# CM32M4xxR register map
Vendor: CMIOT XinSheng Tech Ltd.; File version: 2.0
Registers are 32-bit, read-write, reset 0x0 unless marked. A register's access mark holds for its fields unless they carry their own. Offsets are from the block's base; [hi:lo] are bit positions; {n}, {i} and the like mark numbered series.

## GPIOA — General purpose I/O
Base 0x40010800
Same registers: GPIOB 0x40010C00, GPIOC 0x40011000, GPIOD 0x40011400, GPIOE 0x40011800, GPIOF 0x40011C00, GPIOG 0x40012000
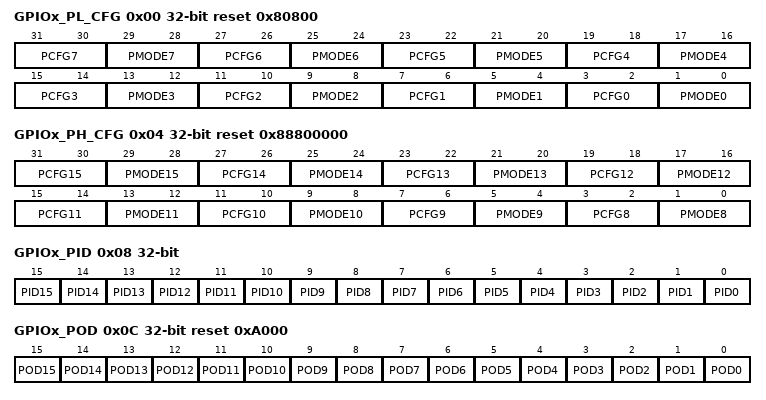
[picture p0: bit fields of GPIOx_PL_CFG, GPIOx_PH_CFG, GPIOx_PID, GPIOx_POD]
0x00 GPIOx_PL_CFG reset 0x80800
  [4n+3:4n+2] PCFG{n} (n=0..7), [4n+1:4n] PMODE{n} (n=0..7)
0x04 GPIOx_PH_CFG reset 0x88800000
  [4n-29:4n-30] PCFG{n} (n=8..15), [4n-31:4n-32] PMODE{n} (n=8..15)
0x08 GPIOx_PID
  [n] PID{n} (n=0..15)
0x0C GPIOx_POD reset 0xA000
  [n] POD{n} (n=0..15)
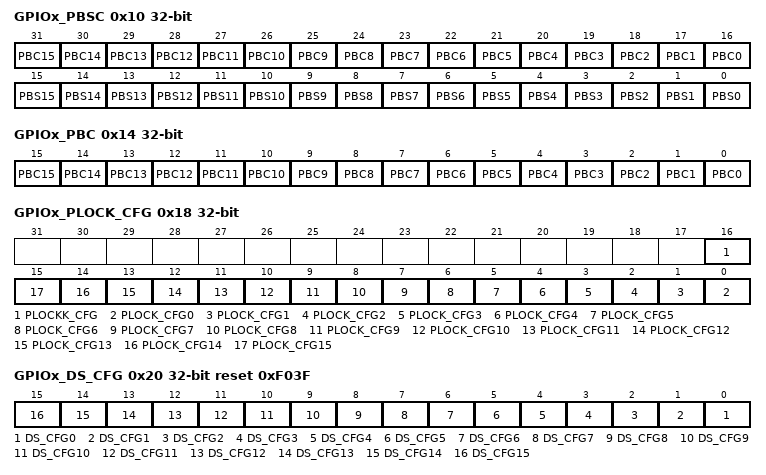
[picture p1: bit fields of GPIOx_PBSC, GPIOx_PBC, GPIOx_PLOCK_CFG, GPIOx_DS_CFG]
0x10 GPIOx_PBSC
  [n+16] PBC{n} (n=0..15), [n] PBS{n} (n=0..15)
0x14 GPIOx_PBC
  [n] PBC{n} (n=0..15)
0x18 GPIOx_PLOCK_CFG
  [16] PLOCKK_CFG, [n] PLOCK_CFG{n} (n=0..15)
0x20 GPIOx_DS_CFG reset 0xF03F
  [n] DS_CFG{n} (n=0..15)
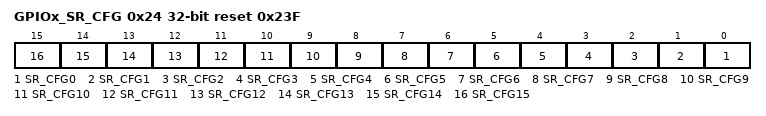
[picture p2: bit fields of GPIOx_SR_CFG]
0x24 GPIOx_SR_CFG reset 0x23F
  [n] SR_CFG{n} (n=0..15)

## AFIO — Alternate function I/O
Base 0x40010000
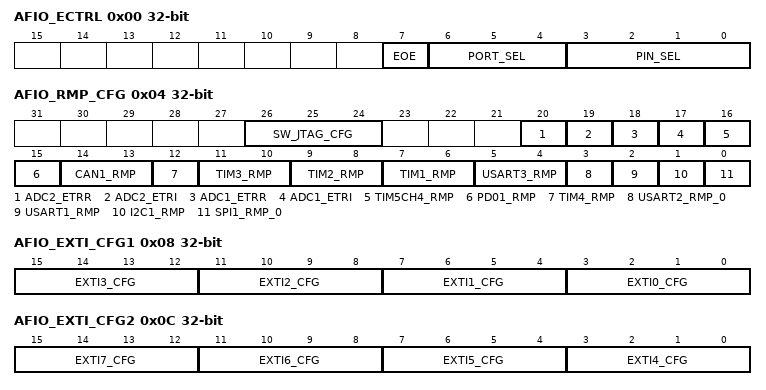
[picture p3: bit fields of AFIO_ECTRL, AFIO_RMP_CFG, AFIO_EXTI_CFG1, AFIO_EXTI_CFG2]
0x00 AFIO_ECTRL
  [7] EOE, [6:4] PORT_SEL, [3:0] PIN_SEL
0x04 AFIO_RMP_CFG
  [26:24] SW_JTAG_CFG, [20] ADC2_ETRR, [19] ADC2_ETRI, [18] ADC1_ETRR, [17] ADC1_ETRI, [16] TIM5CH4_RMP, [15] PD01_RMP, [14:13] CAN1_RMP, [12] TIM4_RMP, [11:10] TIM3_RMP, [9:8] TIM2_RMP, [7:6] TIM1_RMP, [5:4] USART3_RMP, [3] USART2_RMP_0, [2] USART1_RMP, [1] I2C1_RMP, [0] SPI1_RMP_0
0x08 AFIO_EXTI_CFG1
  [4n+3:4n] EXTI{n}_CFG (n=0..3)
0x0C AFIO_EXTI_CFG2
  [4n-13:4n-16] EXTI{n}_CFG (n=4..7)
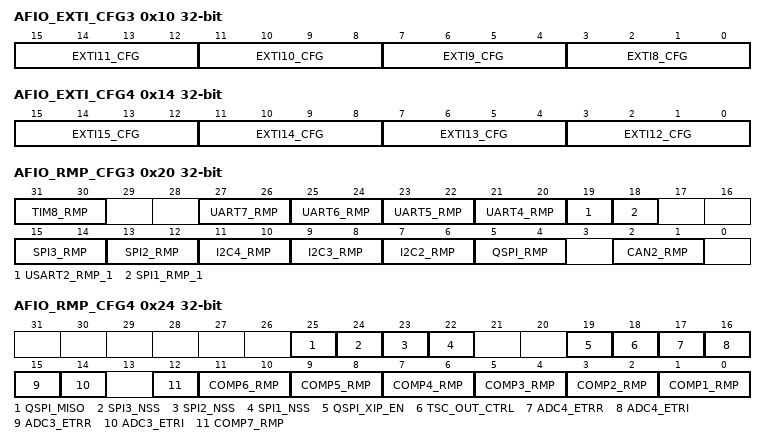
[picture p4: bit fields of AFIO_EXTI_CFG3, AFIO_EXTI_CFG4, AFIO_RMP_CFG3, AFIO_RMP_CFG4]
0x10 AFIO_EXTI_CFG3
  [4n-29:4n-32] EXTI{n}_CFG (n=8..11)
0x14 AFIO_EXTI_CFG4
  [4n-45:4n-48] EXTI{n}_CFG (n=12..15)
0x20 AFIO_RMP_CFG3
  [31:30] TIM8_RMP, [2n+13:2n+12] UART{n}_RMP (n=4..7), [19] USART2_RMP_1, [18] SPI1_RMP_1, [15:14] SPI3_RMP, [13:12] SPI2_RMP, [11:10] I2C4_RMP, [9:8] I2C3_RMP, [7:6] I2C2_RMP, [5:4] QSPI_RMP, [2:1] CAN2_RMP
0x24 AFIO_RMP_CFG4
  [25] QSPI_MISO, [24] SPI3_NSS, [23] SPI2_NSS, [22] SPI1_NSS, [19] QSPI_XIP_EN, [18] TSC_OUT_CTRL, [17] ADC4_ETRR, [16] ADC4_ETRI, [15] ADC3_ETRR, [14] ADC3_ETRI, [12] COMP7_RMP, [2n-1:2n-2] COMP{n}_RMP (n=1..6)
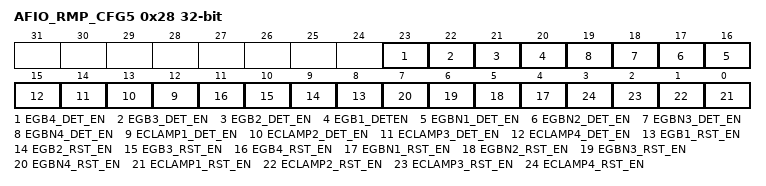
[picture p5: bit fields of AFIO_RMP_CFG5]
0x28 AFIO_RMP_CFG5
  [23] EGB4_DET_EN, [22] EGB3_DET_EN, [21] EGB2_DET_EN, [20] EGB1_DETEN, [n+15] EGBN{n}_DET_EN (n=1..4), [n+11] ECLAMP{n}_DET_EN (n=1..4), [n+7] EGB{n}_RST_EN (n=1..4), [n+3] EGBN{n}_RST_EN (n=1..4), [n-1] ECLAMP{n}_RST_EN (n=1..4)

## EXTI — external interrupt/event controller
Base 0x40010400
0x00 EXTI_IMASK
  [21:0] IMASK
0x04 EXTI_EMASK
  [21:0] EMASK
0x08 EXTI_RT_CFG
  [21:0] RT_CFG
0x0C EXTI_FT_CFG
  [21:0] FT_CFG
0x10 EXTI_SWIE
  [21:0] SWIE
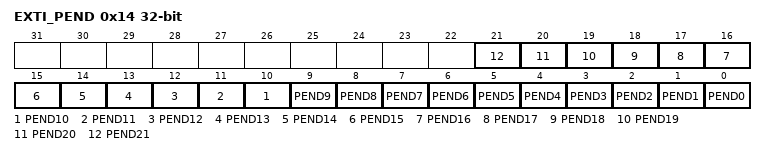
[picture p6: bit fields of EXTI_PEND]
0x14 EXTI_PEND
  [n] PEND{n} (n=0..21)
0x18 EXTI_TS_SEL
  [3:0] TSSEL

## FLASH — interal FLASH controller
Base 0x40022000
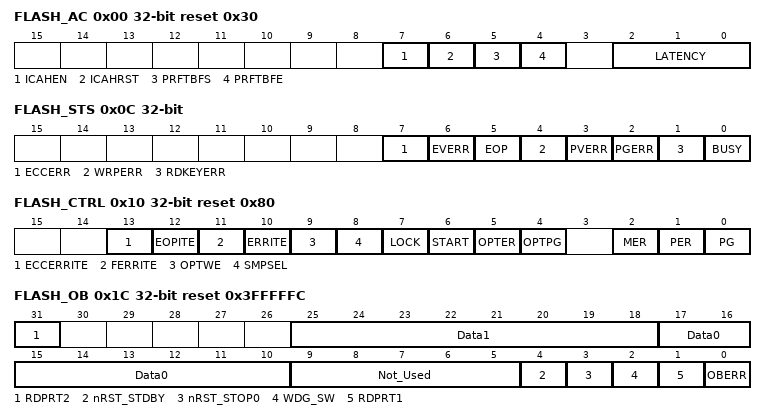
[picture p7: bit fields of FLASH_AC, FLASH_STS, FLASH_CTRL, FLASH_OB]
0x00 FLASH_AC reset 0x30
  [7] ICAHEN, [6] ICAHRST, [5] PRFTBFS, [4] PRFTBFE, [2:0] LATENCY
0x04 FLASH_KEY
  [31:0] FKEY
0x08 FLASH_OPTKEY
0x0C FLASH_STS
  [7] ECCERR, [6] EVERR, [5] EOP, [4] WRPERR, [3] PVERR, [2] PGERR, [1] RDKEYERR, [0] BUSY
0x10 FLASH_CTRL reset 0x80
  [13] ECCERRITE, [12] EOPITE, [11] FERRITE, [10] ERRITE, [9] OPTWE, [8] SMPSEL, [7] LOCK, [6] START, [5] OPTER, [4] OPTPG, [2] MER, [1] PER, [0] PG
0x14 FLASH_ADD
  [31:0] FADD
0x1C FLASH_OB reset 0x3FFFFFC
  [31] RDPRT2, [25:18] Data1, [17:10] Data0, [9:5] Not_Used, [4] nRST_STDBY, [3] nRST_STOP0, [2] WDG_SW, [1] RDPRT1, [0] OBERR
0x20 FLASH_WRP reset 0xFFFFFFFF
  [31:0] WRPT
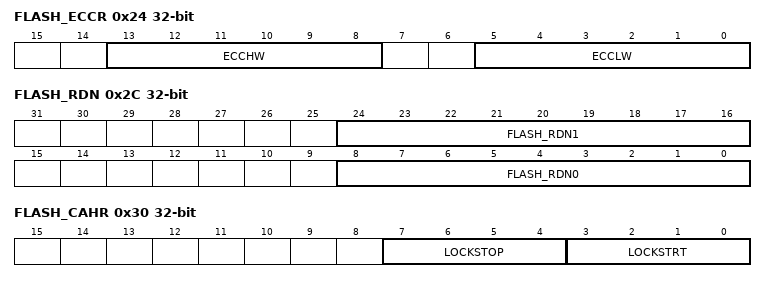
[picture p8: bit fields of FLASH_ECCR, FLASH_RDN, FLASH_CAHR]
0x24 FLASH_ECCR
  [13:8] ECCHW, [5:0] ECCLW
0x2C FLASH_RDN
  [24:16] FLASH_RDN1, [8:0] FLASH_RDN0
0x30 FLASH_CAHR
  [7:4] LOCKSTOP, [3:0] LOCKSTRT

## I2C1 — Inter integrated circuit
Base 0x40005400
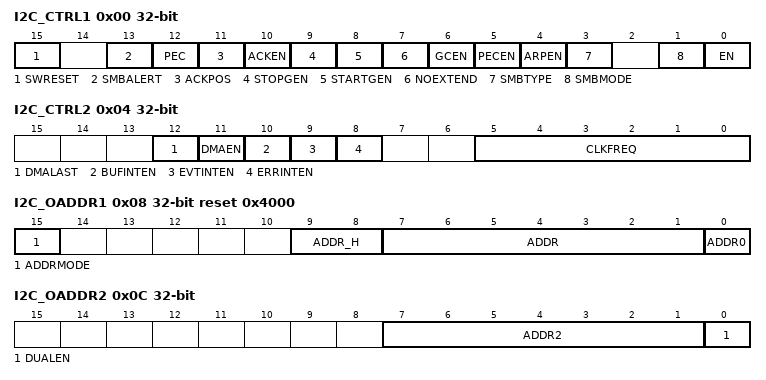
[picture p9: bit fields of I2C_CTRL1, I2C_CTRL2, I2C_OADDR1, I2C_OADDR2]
0x00 I2C_CTRL1
  [15] SWRESET, [13] SMBALERT, [12] PEC, [11] ACKPOS, [10] ACKEN, [9] STOPGEN, [8] STARTGEN, [7] NOEXTEND, [6] GCEN, [5] PECEN, [4] ARPEN, [3] SMBTYPE, [1] SMBMODE, [0] EN
0x04 I2C_CTRL2
  [12] DMALAST, [11] DMAEN, [10] BUFINTEN, [9] EVTINTEN, [8] ERRINTEN, [5:0] CLKFREQ
0x08 I2C_OADDR1 reset 0x4000
  [15] ADDRMODE, [9:8] ADDR_H, [7:1] ADDR, [0] ADDR0
0x0C I2C_OADDR2
  [7:1] ADDR2, [0] DUALEN
0x10 I2C_DAT
  [7:0] DATA
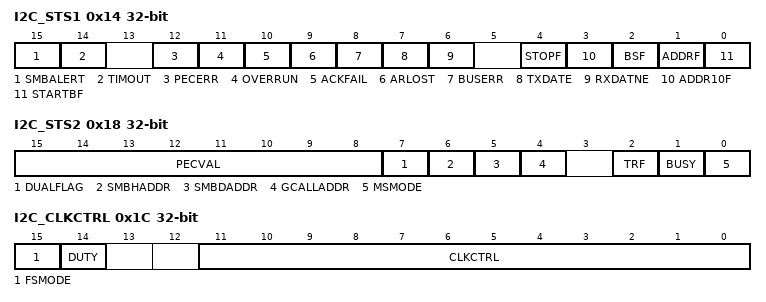
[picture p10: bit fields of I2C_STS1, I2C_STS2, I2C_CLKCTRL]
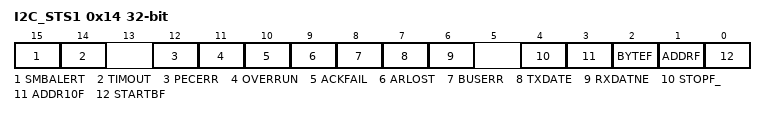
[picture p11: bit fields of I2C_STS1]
0x14 I2C_STS1
  [15] SMBALERT, [14] TIMOUT, [12] PECERR, [11] OVERRUN, [10] ACKFAIL, [9] ARLOST, [8] BUSERR, [7] TXDATE, [6] RXDATNE, [4] STOPF, [3] ADDR10F, [2] BSF, [1] ADDRF, [0] STARTBF
0x18 I2C_STS2
  [15:8] PECVAL, [7] DUALFLAG, [6] SMBHADDR, [5] SMBDADDR, [4] GCALLADDR, [2] TRF, [1] BUSY, [0] MSMODE
0x1C I2C_CLKCTRL
  [15] FSMODE, [14] DUTY, [11:0] CLKCTRL
0x20 I2C_TMRISE
  [5:0] TMRISE

## I2C2 — Inter integrated circuit
Base 0x40005800
Same registers: I2C3 0x40014400, I2C4 0x40014800
Registers as I2C1; these are added or differ:
0x14 I2C_STS1
  [15] SMBALERT, [14] TIMOUT, [12] PECERR, [11] OVERRUN, [10] ACKFAIL, [9] ARLOST, [8] BUSERR, [7] TXDATE, [6] RXDATNE, [4] STOPF_, [3] ADDR10F, [2] BYTEF, [1] ADDRF, [0] STARTBF
